# STM32F398xx register map
File version: 1.0
Registers are 32-bit, read-write, reset 0x0 unless marked. A register's access mark holds for its fields unless they carry their own. Offsets are from the block's base; [hi:lo] are bit positions.

## OPAMP — Operational Amplifier (OPAMP)
Base 0x40010038
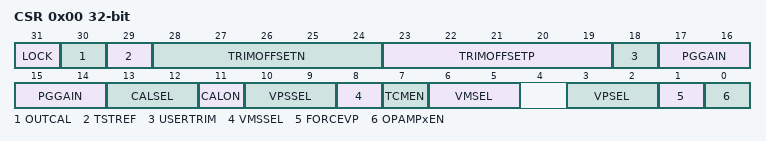
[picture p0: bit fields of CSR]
0x00 CSR — OPAMP control and status register
  [31] LOCK — OPAMP lock
  [30] OUTCAL — OPAMP output status flag
  [29] TSTREF — It enables the switch to put out the internal reference
    0=DISABLE (OPAMP internal reference voltage path to output is disabled.); 1=ENABLE (OPAMP internal reference voltage path to output is enabled.)
  [28:24] TRIMOFFSETN — Offset trimming value (NMOS)
  [23:19] TRIMOFFSETP — Offset trimming value (PMOS)
  [18] USERTRIM — User trimming enable
    0=FACTORY (OPAMP trimming factors set to factory values); 1=USER (OPAMP trimming factors set to user values)
  [17:14] PGGAIN — Gain in PGA mode
  [13:12] CALSEL — Calibration selection
  [11] CALON — Calibration mode enable
    0=FUNCTIONAL (OPAMP functional mode); 1=CALIBRATION (OPAMP calibration mode)
  [10:9] VPSSEL — Non inverting input secondary selection
    3=NONINVERT_IO0_SEC (OPAMP non inverting input secondary connected to GPIO pin (pin PA1 for OPAMP1, pin PA7 for OPAMP2, pin PB0 for OPAMP3, pin PB13 for OPAMP4)); 0=NONINVERT_IO1_SEC (OPAMP non inverting input secondary connected to GPIO pin (pin PA7 for OPAMP1, pin PD14 for OPAMP2, pin PB13 for OPAMP3, pin PD11 for OPAMP4)); 2=NONINVERT_IO2_SEC (OPAMP non inverting input secondary connected to GPIO pin (pin PA3 for OPAMP1, pin PB0 for OPAMP2, pin PA1 for OPAMP3, pin PB11 for OPAMP4)); 1=NONINVERT_IO3_SEC (OPAMP non inverting input secondary connected to GPIO pin (pin PA5 for OPAMP1, pin PD14 for OPAMP2, pin PA5 for OPAMP3, pin PA4 for OPAMP4))
  [8] VMSSEL — Inverting input secondary selection
    0=IO0_SEC (OPAMP inverting input secondary connected to GPIO pin (pin PC5 for OPAMP1, pin PC5 for OPAMP2, pin PB10 for OPAMP3, pin PB10 for OPAMP4). Note: OPAMP inverting input is used with OPAMP in mode standalone or PGA with external capacitors for filtering circuit. Otherwise (OPAMP in mode follower), OPAMP inverting input is not used (not connected to GPIO pin).); 1=IO1_SEC (OPAMP inverting input secondary connected to GPIO pin (pin PA3 for OPAMP1, pin PA5 for OPAMP2, pin PB2 for OPAMP3, pin PD8 for OPAMP4). Note: OPAMP inverting input is used with OPAMP in mode standalone or PGA with external capacitors for filtering circuit. Otherwise (OPAMP in mode follower), OPAMP inverting input is not used (not connected to GPIO pin).)
  [7] TCMEN — Timer-Controlled Mux mode enable
    0=DISABLE (OPAMP inputs multiplexer mode dosabled.); 1=TIM1_CH6 (OPAMP inputs multiplexer mode enabled, controlled by TIM1 CC6.)
  [6:5] VMSEL — Inverting input selection
    0=IO0 (OPAMP inverting input connected to GPIO pin (pin PC5 for OPAMP1, pin PC5 for OPAMP2, pin PB10 for OPAMP3, pin PB10 for OPAMP4). Note: OPAMP inverting input is used with OPAMP in mode standalone or PGA with external capacitors for filtering circuit. Otherwise (OPAMP in mode follower), OPAMP inverting input is not used (not connected to GPIO pin).); 1=IO1 (OPAMP inverting input connected to GPIO pin (pin PA3 for OPAMP1, pin PA5 for OPAMP2, pin PB2 for OPAMP3, pin PD8 for OPAMP4). Note: OPAMP inverting input is used with OPAMP in mode standalone or PGA with external capacitors for filtering circuit. Otherwise (OPAMP in mode follower), OPAMP inverting input is not used (not connected to GPIO pin).); 2=CONNECT_NO (OPAMP inverting input not externally connected (intended for OPAMP in mode follower or PGA without external capacitors for filtering). Note: On this STM32 series, this literal include cases of value 0x11 for mode follower and value 0x10 for mode PGA.)
  [3:2] VPSEL — Non inverting input selection
    3=NONINVERT_IO0 (OPAMP non inverting input connected to GPIO pin (pin PA1 for OPAMP1, pin PA7 for OPAMP2, pin PB0 for OPAMP3, pin PB13 for OPAMP4)); 0=NONINVERT_IO1 (OPAMP non inverting input connected to GPIO pin (pin PA7 for OPAMP1, pin PD14 for OPAMP2, pin PB13 for OPAMP3, pin PD11 for OPAMP4)); 2=NONINVERT_IO2 (OPAMP non inverting input connected to GPIO pin (pin PA3 for OPAMP1, pin PB0 for OPAMP2, pin PA1 for OPAMP3, pin PA4 for OPAMP4)); 1=NONINVERT_IO3 (OPAMP non inverting input connected to GPIO pin (pin PA5 for OPAMP1, pin PB14 for OPAMP2, pin PA5 for OPAMP3, pin PB11 for OPAMP4))
  [1] FORCEVP — Connect the internal references to the plus input of the OPAMPX
  [0] OPAMPxEN — OPAMP enable
